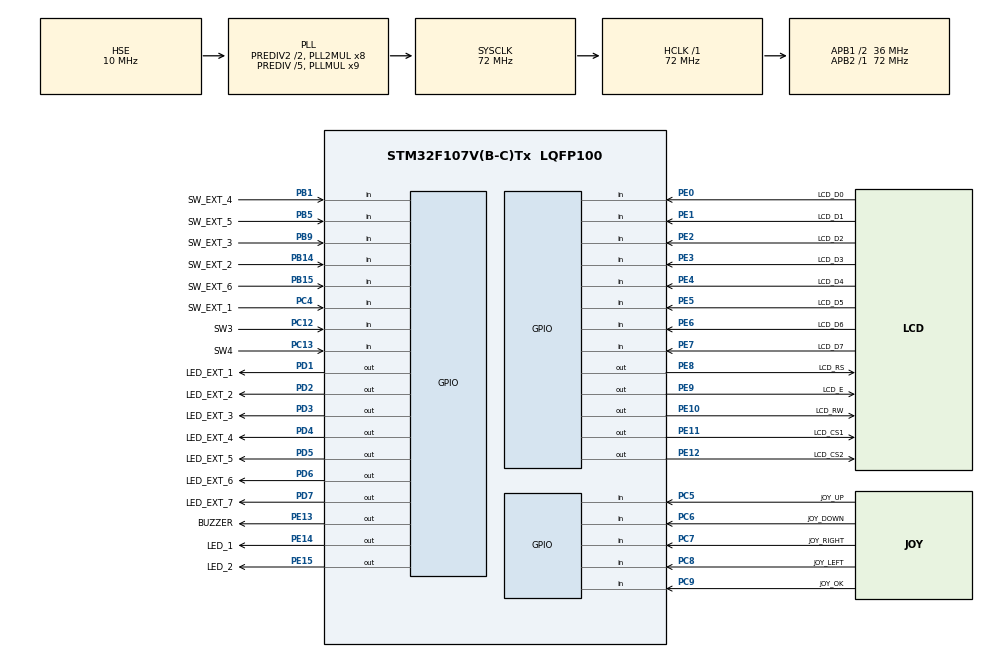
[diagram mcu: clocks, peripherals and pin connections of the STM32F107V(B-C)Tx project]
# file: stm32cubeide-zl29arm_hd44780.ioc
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Mcu.Family=STM32F1
Mcu.Name=STM32F107V(B-C)Tx
Mcu.Package=LQFP100
NVIC.PriorityGroup=NVIC_PRIORITYGROUP_4
NVIC.TIM7_IRQn=true\:0\:0\:false\:false\:true\:true\:true\:true
OSC_IN.Mode=HSE-External-Oscillator
OSC_IN.Signal=RCC_OSC_IN
OSC_OUT.Mode=HSE-External-Oscillator
OSC_OUT.Signal=RCC_OSC_OUT
PA13.Mode=Trace_Asynchronous_SW
PA13.Signal=SYS_JTMS-SWDIO
PA14.Mode=Trace_Asynchronous_SW
PA14.Signal=SYS_JTCK-SWCLK
PB1.GPIO_Label=SW_EXT_4
PB1.Signal=GPIO_Input
PB14.GPIO_Label=SW_EXT_2
PB14.Signal=GPIO_Input
PB15.GPIO_Label=SW_EXT_6
PB15.Signal=GPIO_Input
PB3.Mode=Trace_Asynchronous_SW
PB3.Signal=SYS_TRACESWO
PB5.GPIO_Label=SW_EXT_5
PB5.Signal=GPIO_Input
PB9.GPIO_Label=SW_EXT_3
PB9.Signal=GPIO_Input
PC12.GPIO_Label=SW3
PC12.Signal=GPIO_Input
PC13-TAMPER-RTC.GPIO_Label=SW4
PC13-TAMPER-RTC.Signal=GPIO_Input
PC4.GPIO_Label=SW_EXT_1
PC4.Signal=GPIO_Input
PC5.GPIO_Label=JOY_UP
PC5.Signal=GPIO_Input
PC6.GPIO_Label=JOY_DOWN
PC6.Signal=GPIO_Input
PC7.GPIO_Label=JOY_RIGHT
PC7.Signal=GPIO_Input
PC8.GPIO_Label=JOY_LEFT
PC8.Signal=GPIO_Input
PC9.GPIO_Label=JOY_OK
PC9.Signal=GPIO_Input
PD1.GPIO_Label=LED_EXT_1
PD1.Signal=GPIO_Output
PD2.GPIO_Label=LED_EXT_2
PD2.Signal=GPIO_Output
PD3.GPIO_Label=LED_EXT_3
PD3.Signal=GPIO_Output
PD4.GPIO_Label=LED_EXT_4
PD4.Signal=GPIO_Output
PD5.GPIO_Label=LED_EXT_5
PD5.Signal=GPIO_Output
PD6.GPIO_Label=LED_EXT_6
PD6.Signal=GPIO_Output
PD7.GPIO_Label=LED_EXT_7
PD7.Signal=GPIO_Output
PE0.GPIO_Label=LCD_D0
PE0.Signal=GPIO_Input
PE1.GPIO_Label=LCD_D1
PE1.GPIO_Mode=GPIO_MODE_INPUT
PE1.GPIO_PuPd=GPIO_NOPULL
PE1.Signal=GPIO_Input
PE10.GPIO_Label=LCD_RW
PE10.Signal=GPIO_Output
PE11.GPIO_Label=LCD_CS1
PE11.Signal=GPIO_Output
PE12.GPIO_Label=LCD_CS2
PE12.Signal=GPIO_Output
PE13.GPIO_Label=BUZZER
PE13.GPIO_ModeDefaultOutputPP=GPIO_MODE_OUTPUT_PP
PE13.Signal=GPIO_Output
PE14.GPIO_Label=LED_1
PE14.GPIO_ModeDefaultOutputPP=GPIO_MODE_OUTPUT_OD
PE14.PinState=GPIO_PIN_SET
PE14.Signal=GPIO_Output
PE15.GPIO_Label=LED_2
PE15.GPIO_ModeDefaultOutputPP=GPIO_MODE_OUTPUT_OD
PE15.PinState=GPIO_PIN_SET
PE15.Signal=GPIO_Output
PE2.GPIO_Label=LCD_D2
PE2.GPIO_Mode=GPIO_MODE_INPUT
PE2.GPIO_PuPd=GPIO_NOPULL
PE2.Signal=GPIO_Input
PE3.GPIO_Label=LCD_D3
PE3.GPIO_Mode=GPIO_MODE_INPUT
PE3.GPIO_PuPd=GPIO_NOPULL
PE3.Signal=GPIO_Input
PE4.GPIO_Label=LCD_D4
PE4.GPIO_Mode=GPIO_MODE_INPUT
PE4.GPIO_PuPd=GPIO_NOPULL
PE4.Signal=GPIO_Input
PE5.GPIO_Label=LCD_D5
PE5.GPIO_Mode=GPIO_MODE_INPUT
PE5.GPIO_PuPd=GPIO_NOPULL
PE5.Signal=GPIO_Input
PE6.GPIO_Label=LCD_D6
PE6.GPIO_Mode=GPIO_MODE_INPUT
PE6.GPIO_PuPd=GPIO_NOPULL
PE6.Signal=GPIO_Input
PE7.GPIO_Label=LCD_D7
PE7.GPIO_Mode=GPIO_MODE_INPUT
PE7.GPIO_PuPd=GPIO_NOPULL
PE7.Signal=GPIO_Input
PE8.GPIO_Label=LCD_RS
PE8.Signal=GPIO_Output
PE9.GPIO_Label=LCD_E
PE9.Signal=GPIO_Output
ProjectManager.HeapSize=0x200
ProjectManager.StackSize=0x400
ProjectManager.TargetToolchain=STM32CubeIDE
RCC.AHBFreq_Value=72000000
RCC.APB1CLKDivider=RCC_HCLK_DIV2
RCC.APB1Freq_Value=36000000
RCC.APB1TimFreq_Value=72000000
RCC.APB2Freq_Value=72000000
RCC.APB2TimFreq_Value=72000000
RCC.HCLKFreq_Value=72000000
RCC.HSEDivPLL=RCC_HSE_PREDIV_DIV5
RCC.HSE_VALUE=10000000
RCC.PLLMUL=RCC_PLL_MUL9
RCC.PLLSourceVirtual=RCC_PLLSOURCE_HSE
RCC.Prediv1Source=RCC_PREDIV1_SOURCE_PLL2
RCC.Prediv2=RCC_HSE_PREDIV2_DIV2
RCC.SYSCLKFreq_VALUE=72000000
RCC.SYSCLKSource=RCC_SYSCLKSOURCE_PLLCLK
RCC.USBFreq_Value=48000000
TIM7.Period=1000
TIM7.Prescaler=7200
VP_TIM7_VS_ClockSourceINT.Mode=Enable_Timer
board=zl29arm

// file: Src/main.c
/* USER CODE BEGIN Header */
/**
  ******************************************************************************
  * @file           : main.c
  * @brief          : Main program body
  ******************************************************************************
  * @attention
  *
  * <h2><center>&copy; Copyright (c) 2024 STMicroelectronics.
  * All rights reserved.</center></h2>
  *
  * This software component is licensed by ST under BSD 3-Clause license,
  * the "License"; You may not use this file except in compliance with the
  * License. You may obtain a copy of the License at:
  *                        opensource.org/licenses/BSD-3-Clause
  *
  ******************************************************************************
  */
/* USER CODE END Header */
#include "main.h"
#include "tim.h"
#include "gpio.h"

/* USER CODE BEGIN Includes */
#include "../inc/lcd_hd44780_lib.h"
#include <stdio.h>
#include <stdint.h>
/* USER CODE END Includes */

void SystemClock_Config(void);

int main(void)
{

  /* MCU Configuration--------------------------------------------------------*/

  /* Reset of all peripherals, Initializes the Flash interface and the Systick. */
  HAL_Init();

  /* Configure the system clock */
  SystemClock_Config();

  /* Initialize all configured peripherals */
  MX_GPIO_Init();
  MX_TIM7_Init();
  /* USER CODE BEGIN 2 */

  LCD_Initialize();
  LCD_GoTo(0, 0);
  LCD_WriteText("test");

  /* USER CODE END 2 */

  /* Infinite loop */
  while (1)
  {

  }
}

void SystemClock_Config(void)
{
  RCC_OscInitTypeDef RCC_OscInitStruct = {0};
  RCC_ClkInitTypeDef RCC_ClkInitStruct = {0};

  /** Initializes the RCC Oscillators according to the specified parameters
  * in the RCC_OscInitTypeDef structure.
  */
  RCC_OscInitStruct.OscillatorType = RCC_OSCILLATORTYPE_HSE;
  RCC_OscInitStruct.HSEState = RCC_HSE_ON;
  RCC_OscInitStruct.HSEPredivValue = RCC_HSE_PREDIV_DIV5;
  RCC_OscInitStruct.HSIState = RCC_HSI_ON;
  RCC_OscInitStruct.Prediv1Source = RCC_PREDIV1_SOURCE_PLL2;
  RCC_OscInitStruct.PLL.PLLState = RCC_PLL_ON;
  RCC_OscInitStruct.PLL.PLLSource = RCC_PLLSOURCE_HSE;
  RCC_OscInitStruct.PLL.PLLMUL = RCC_PLL_MUL9;
  RCC_OscInitStruct.PLL2.PLL2State = RCC_PLL2_ON;
  RCC_OscInitStruct.PLL2.PLL2MUL = RCC_PLL2_MUL8;
  RCC_OscInitStruct.PLL2.HSEPrediv2Value = RCC_HSE_PREDIV2_DIV2;
  if (HAL_RCC_OscConfig(&RCC_OscInitStruct) != HAL_OK)
  {
    Error_Handler();
  }

  /** Initializes the CPU, AHB and APB buses clocks
  */
  RCC_ClkInitStruct.ClockType = RCC_CLOCKTYPE_HCLK|RCC_CLOCKTYPE_SYSCLK
                              |RCC_CLOCKTYPE_PCLK1|RCC_CLOCKTYPE_PCLK2;
  RCC_ClkInitStruct.SYSCLKSource = RCC_SYSCLKSOURCE_PLLCLK;
  RCC_ClkInitStruct.AHBCLKDivider = RCC_SYSCLK_DIV1;
  RCC_ClkInitStruct.APB1CLKDivider = RCC_HCLK_DIV2;
  RCC_ClkInitStruct.APB2CLKDivider = RCC_HCLK_DIV1;

  if (HAL_RCC_ClockConfig(&RCC_ClkInitStruct, FLASH_LATENCY_2) != HAL_OK)
  {
    Error_Handler();
  }

  /** Configure the Systick interrupt time
  */
  __HAL_RCC_PLLI2S_ENABLE();
}

void Error_Handler(void)
{
  __disable_irq();
  while (1)
  {
  }
}
